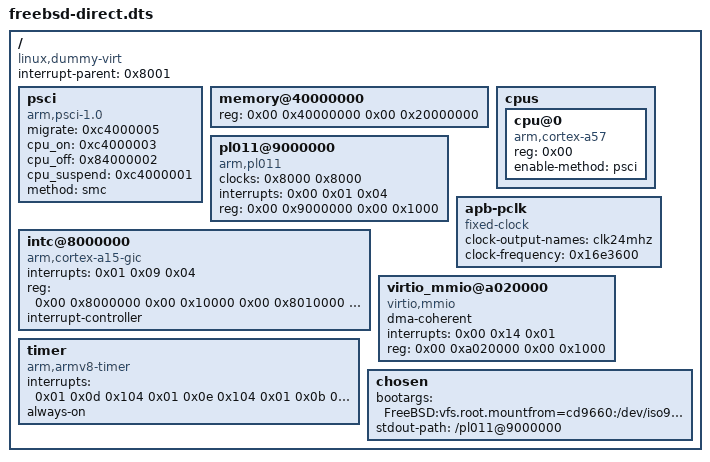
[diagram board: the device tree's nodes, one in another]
/dts-v1/;

/*
 * freebsd-direct.dts — Direct FreeBSD kernel FDT for QEMU virt/aarch64.
 *
 * Memory layout (must match freebsd_vmm.c and system_desc_aarch64.c):
 *   512 MB (0x20000000) at guest phys 0x40000000
 *
 * PSCI: SMC method — seL4 intercepts HVC from VCPU EL1 as a seL4 syscall,
 * not a VCPUFault, so we use SMC.  libvmm fault.c routes SMC to handle_psci().
 *
 * Boot arguments must start with "FreeBSD:"; the arm64 kernel intentionally
 * ignores generic Linux-style bootargs without that prefix.
 */

/ {
	interrupt-parent = <0x8001>;
	#size-cells = <0x02>;
	#address-cells = <0x02>;
	compatible = "linux,dummy-virt";

	psci {
		migrate = <0xc4000005>;
		cpu_on = <0xc4000003>;
		cpu_off = <0x84000002>;
		cpu_suspend = <0xc4000001>;
		method = "smc";
		compatible = "arm,psci-1.0\0arm,psci-0.2\0arm,psci";
	};

	/* 512 MB — matches guest_ram MR size in the aarch64 system descriptor. */
	memory@40000000 {
		reg = <0x00 0x40000000 0x00 0x20000000>;
		device_type = "memory";
	};

	pl011@9000000 {
		clock-names = "uartclk\0apb_pclk";
		clocks = <0x8000 0x8000>;
		interrupts = <0x00 0x01 0x04>;
		reg = <0x00 0x9000000 0x00 0x1000>;
		compatible = "arm,pl011\0arm,primecell";
	};

	/* GIC: distributor + CPU interface + hypervisor + virtual CPU interface */
	intc@8000000 {
		phandle = <0x8001>;
		interrupts = <0x01 0x09 0x04>;
		reg = <0x00 0x8000000 0x00 0x10000
		       0x00 0x8010000 0x00 0x10000
		       0x00 0x8030000 0x00 0x10000
		       0x00 0x8040000 0x00 0x10000>;
		compatible = "arm,cortex-a15-gic";
		ranges;
		#size-cells = <0x02>;
		#address-cells = <0x02>;
		interrupt-controller;
		#interrupt-cells = <0x03>;
	};

	cpus {
		#size-cells = <0x00>;
		#address-cells = <0x01>;

		cpu@0 {
			reg = <0x00>;
			enable-method = "psci";
			compatible = "arm,cortex-a57";
			device_type = "cpu";
		};
	};

	timer {
		interrupts = <0x01 0x0d 0x104
		              0x01 0x0e 0x104
		              0x01 0x0b 0x104
		              0x01 0x0a 0x104>;
		always-on;
		compatible = "arm,armv8-timer\0arm,armv7-timer";
	};

	apb-pclk {
		phandle = <0x8000>;
		clock-output-names = "clk24mhz";
		clock-frequency = <0x16e3600>;
		#clock-cells = <0x00>;
		compatible = "fixed-clock";
	};

	/*
	 * agentOS-emulated VirtIO block endpoint. The IPA is deliberately outside
	 * QEMU's virtio-mmio transport window and remains unmapped so accesses
	 * fault to freebsd_vmm. Host media is reachable only through BlockService.
	 */
	virtio_mmio@a020000 {
		dma-coherent;
		interrupts = <0x00 0x14 0x01>;
		reg = <0x00 0xa020000 0x00 0x1000>;
		compatible = "virtio,mmio";
	};

	chosen {
		bootargs = "FreeBSD:vfs.root.mountfrom=cd9660:/dev/iso9660/15_0_RELEASE_AARCH64_DVD console=ttyu0 boot_serial=YES";
		/* This PL011 is fault-emulated by freebsd_vmm and drained via CC-PD. */
		stdout-path = "/pl011@9000000";
	};
};
